# Cortex_M52 register map
Vendor: Arm Ltd.; Series: ARMv8.1-M Mainline; File version: 1.0.0
CPU: other r0p0, little endian, MPU, FPU, double-precision FPU, DSP, 8 interrupt priority bits
Registers are 32-bit, read-write, reset 0x0 unless marked. A register's access mark holds for its fields unless they carry their own. Offsets are from the block's base; [hi:lo] are bit positions; {n}, {i} and the like mark numbered series.

## DCAR — Direct Cache Access Registers (Cortex-M52): read cache RAM contents by location for test and diagnostics.
Base 0xE001E200
0x00 DCADCRR — Direct Cache Access Data Cache Read Register: the data read from the D-cache location selected in DCADCLR.
0x04 DCAICRR — Direct Cache Access Instruction Cache Read Register: the data read from the I-cache location selected in DCAICLR.
0x10 DCADCLR — Direct Cache Access Data Cache Location Register: set, way and word of the D-cache entry to read.
0x14 DCAICLR — Direct Cache Access Instruction Cache Location Register: set, way and word of the I-cache entry to read.

## PWRMODCTL — Power Mode Control (Cortex-M55/M85/M52): the low-power state (ON / retention / OFF) requested for the core, EPU and RAM power domains when the processor sleeps.
Base 0xE001E300
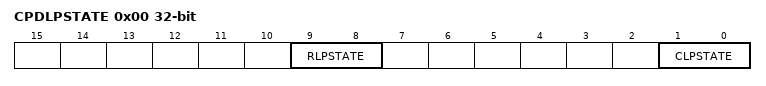
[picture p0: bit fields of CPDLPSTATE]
0x00 CPDLPSTATE — Core Power Domain Low Power State Register: the power state requested for the core, EPU (FPU/MVE) and RAM domains on deep sleep.
  [9:8] RLPSTATE — RAM (caches/TCM) low-power state: 0 = ON, 2 = retention, 3 = OFF.
  [1:0] CLPSTATE — Core low-power state requested on deep sleep: 0 = ON, 1 = ON with the clock stopped, 2 = retention, 3 = OFF.
0x04 DPDLPSTATE — Debug Power Domain Low Power State Register: the power state requested for the debug domain.
  [1:0] DLPSTATE — Debug power domain low-power state: 0 = ON, 2 = retention, 3 = OFF.

## EWIC_ISA — EWIC Interrupt Status Access: the processor-side view of the EWIC - set an event pending and read back the mask configuration.
Base 0xE001E400
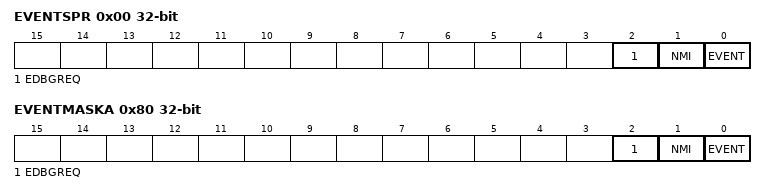
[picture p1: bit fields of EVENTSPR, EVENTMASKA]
0x00 EVENTSPR wo — Event Set Pending Register: software writes to latch an event as if it had arrived.
  [2] EDBGREQ — Write 1 to latch an external debug request.
  [1] NMI — Write 1 to latch an NMI.
  [0] EVENT — Write 1 to latch an EVENT.
0x80 EVENTMASKA ro — Event Mask A Register: read-only copy of EWIC_MASKA.
  [2] EDBGREQ — Wake on external debug request is enabled.
  [1] NMI — Wake on NMI is enabled.
  [0] EVENT — Wake on EVENT is enabled.
{0x80+4i} EVENTMASK{i} (i=1..15) ro — Event Mask Register n: read-only copy of EWIC_MASKn.
  [31:0] IRQ — Bit k = 1: wake on IRQ 32(n-1)+k is enabled.

## PRCCFGINF — Processor Configuration Information: indexed read access to the build-time configuration of the core (cache/TCM sizes, options).
Base 0xE001E700
0x00 CFGINFOSEL wo — Processor Configuration Information Selection Register: write the index of the configuration word to read from CFGINFORD.
  [31:0] SEL — Index of the configuration information word to read.
0x04 CFGINFORD ro — Processor Configuration Information Read Data Register: the configuration word selected by CFGINFOSEL.
  [31:0] DATA — Configuration information word.

## STL — Software Test Library support registers (Cortex-M55/M85): expose internal NVIC priority-tree, MPU lookup, store buffer and line-fill state for functional-safety self test.
Base 0xE001E800
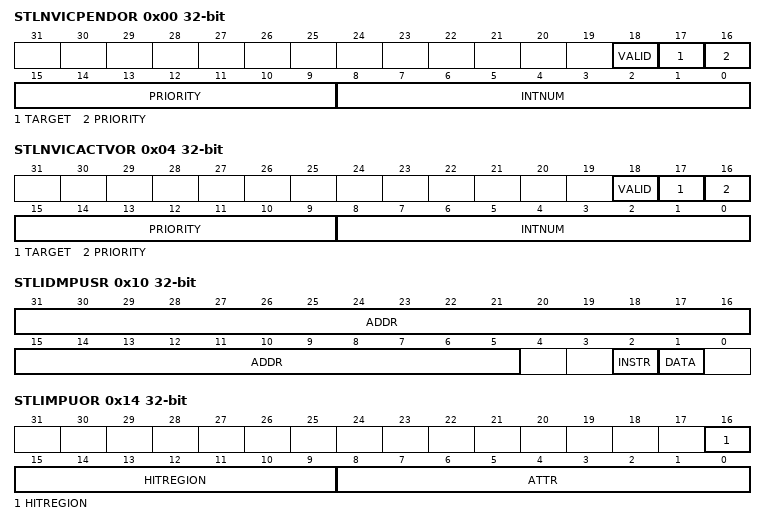
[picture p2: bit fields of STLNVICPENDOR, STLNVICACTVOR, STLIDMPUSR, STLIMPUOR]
0x00 STLNVICPENDOR ro — NVIC Pending Priority Tree Register: the output of the NVIC pending-priority tree (highest-priority pending interrupt).
  [18] VALID — 1 = an interrupt is pending (the other fields are valid).
  [17] TARGET — Its target security state: 0 = Secure, 1 = Non-secure.
  [16:9] PRIORITY — Its priority.
  [8:0] INTNUM — Interrupt number of the highest-priority pending interrupt.
0x04 STLNVICACTVOR ro — NVIC Active Priority Tree Register: the output of the NVIC active-priority tree (highest-priority active interrupt).
  [18] VALID — 1 = an interrupt is active (the other fields are valid).
  [17] TARGET — Its target security state: 0 = Secure, 1 = Non-secure.
  [16:9] PRIORITY — Its priority.
  [8:0] INTNUM — Interrupt number of the highest-priority active interrupt.
0x10 STLIDMPUSR wo — MPU Sample Register: write an address and side to perform a test MPU lookup whose results appear in STLIMPUOR / STLDnMPUOR.
  [31:5] ADDR — Address to look up, bits [31:5].
  [2] INSTR — Perform an instruction-side MPU lookup.
  [1] DATA — Perform a data-side MPU lookup.
0x14 STLIMPUOR ro — MPU Region Hit Register: instruction-side result of the STLIDMPUSR lookup.
  [16:9] HITREGION — Region number that matched (instruction side).
  [8:0] ATTR — Attributes returned by the instruction-side lookup.
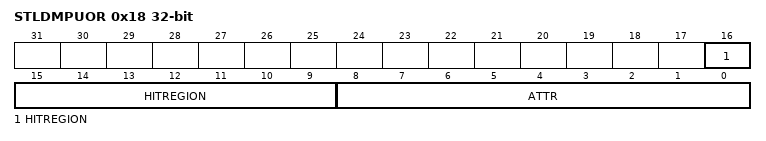
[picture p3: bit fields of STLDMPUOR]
0x18 STLDMPUOR ro — MPU Memory Attributes Register: data-side result of the STLIDMPUSR lookup.
  [16:9] HITREGION — Region number that matched (data side).
  [8:0] ATTR — Attributes returned by the data-side lookup.

## EWIC — External Wakeup Interrupt Controller: latches interrupt, NMI and event inputs while the processor is powered down and wakes it. Configure the masks before sleeping.
Base 0xE0047000
0x00 EWIC_CR — EWIC Control Register: global enable.
  [0] EN — EWIC enable. Set before powering down so wake-up events are latched.
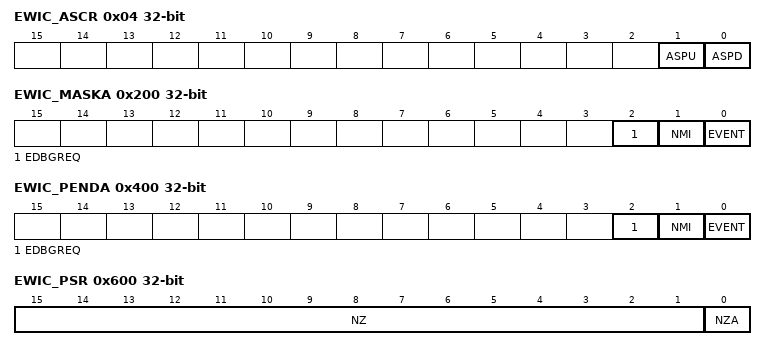
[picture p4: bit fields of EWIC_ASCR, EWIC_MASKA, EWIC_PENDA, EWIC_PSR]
0x04 EWIC_ASCR — EWIC Automatic Sequence Control Register: automatic mask/unmask sequencing on power-down and power-up.
  [1] ASPU — Automatic sequence on power-up: 1 = latched events are transferred to the NVIC automatically on power-up.
  [0] ASPD — Automatic sequence on power-down: 1 = the EWIC copies the NVIC enables into its masks automatically when the processor powers down.
0x08 EWIC_CLRMASK wo — EWIC Clear Mask Register: write to clear all mask registers.
  [31:0] CLRMASK — Write to clear all EWIC mask registers.
0x0C EWIC_NUMID ro — EWIC Event Number ID Register: how many events (interrupts plus NMI/EVENT/EDBGREQ) the EWIC handles.
  [15:0] NUMEVENT — Number of events supported.
0x200 EWIC_MASKA — EWIC Mask A Register: wake-up enables for the non-interrupt events (EVENT, NMI, EDBGREQ).
  [2] EDBGREQ — Wake on an external debug request.
  [1] NMI — Wake on NMI.
  [0] EVENT — Wake on the EVENT (RXEV) input.
{0x200+4i} EWIC_MASK{i} (i=1..15) — EWIC Mask Register n: bit k enables wake-up on IRQ 32(n-1)+k.
  [31:0] IRQ — Bit k = 1: wake on IRQ 32(n-1)+k.
0x400 EWIC_PENDA ro — EWIC Pend A Register: which non-interrupt events have been latched.
  [2] EDBGREQ — External debug request was latched.
  [1] NMI — NMI was latched.
  [0] EVENT — EVENT input was latched.
{0x400+4i} EWIC_PEND{i} (i=1..15) — EWIC Pend Register n: bit k = IRQ 32(n-1)+k has been latched while the processor was powered down.
  [31:0] IRQ — Bit k = 1: IRQ 32(n-1)+k was latched.
0x600 EWIC_PSR ro — EWIC Pend Summary Register: which PEND registers hold at least one latched event.
  [15:1] NZ — Bit n-1 = 1: EWIC_PENDn is non-zero.
  [0] NZA — EWIC_PENDA is non-zero.
